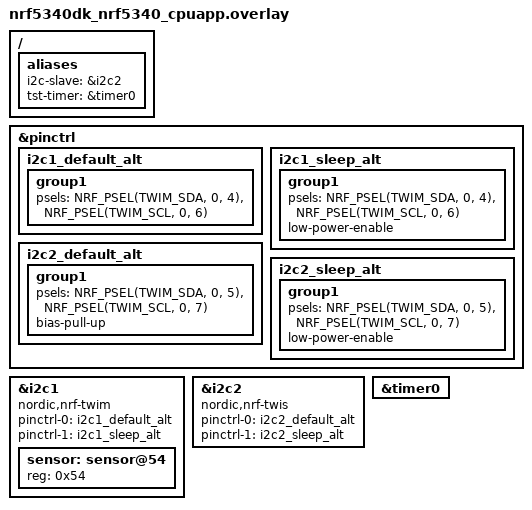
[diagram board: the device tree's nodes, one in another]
/ {
	aliases {
		i2c-slave = &i2c2;
		tst-timer = &timer0;
	};
};

&pinctrl {
	i2c1_default_alt: i2c1_default_alt {
		group1 {
			psels = <NRF_PSEL(TWIM_SDA, 0, 4)>,
				<NRF_PSEL(TWIM_SCL, 0, 6)>;
		};
	};

	i2c1_sleep_alt: i2c1_sleep_alt {
		group1 {
			psels = <NRF_PSEL(TWIM_SDA, 0, 4)>,
				<NRF_PSEL(TWIM_SCL, 0, 6)>;
			low-power-enable;
		};
	};

	i2c2_default_alt: i2c2_default_alt {
		group1 {
			psels = <NRF_PSEL(TWIM_SDA, 0, 5)>,
				<NRF_PSEL(TWIM_SCL, 0, 7)>;
			bias-pull-up;
		};
	};

	i2c2_sleep_alt: i2c2_sleep_alt {
		group1 {
			psels = <NRF_PSEL(TWIM_SDA, 0, 5)>,
				<NRF_PSEL(TWIM_SCL, 0, 7)>;
			low-power-enable;
		};
	};
};

dut_twim: &i2c1 {
	compatible = "nordic,nrf-twim";
	status = "okay";
	pinctrl-0 = <&i2c1_default_alt>;
	pinctrl-1 = <&i2c1_sleep_alt>;
	pinctrl-names = "default", "sleep";
	sensor: sensor@54 {
		reg = <0x54>;
	};
};

dut_twis: &i2c2 {
	compatible = "nordic,nrf-twis";
	pinctrl-0 = <&i2c2_default_alt>;
	pinctrl-1 = <&i2c2_sleep_alt>;
	pinctrl-names = "default", "sleep";
};

&timer0 {
	status = "okay";
};
